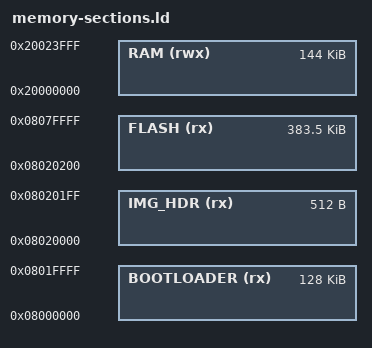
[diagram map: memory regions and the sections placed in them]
/* STM32G0B1RET6 Memory layput */
MEMORY
{
	BOOTLOADER 	(rx)	: ORIGIN = 0x08000000, LENGTH = 0x00020000
	IMG_HDR 	(rx)	: ORIGIN = 0x08020000, LENGTH = 0x00000200
	FLASH 		(rx)	: ORIGIN = 0x08020200, LENGTH = 0x0005FE00
	RAM 		(rwx)	: ORIGIN = 0x20000000, LENGTH = 0x00024000
}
